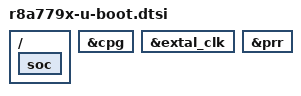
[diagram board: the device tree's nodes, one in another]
// SPDX-License-Identifier: GPL-2.0
/*
 * Device Tree Source extras for U-Boot on RCar Gen3
 *
 * Copyright (C) 2018 Marek Vasut <marek.vasut@gmail.com>
 */

/ {
	soc {
		u-boot,dm-all;
	};
};

&cpg {
	u-boot,dm-all;
};

&extal_clk {
	u-boot,dm-all;
};

&prr {
	u-boot,dm-all;
};
